# RK3399-AP register map
File version: 1
CPU: CA7 r0p1, little endian, MPU, FPU, I-cache, D-cache, VTOR, 4 interrupt priority bits, 0 interrupts
Registers are 32-bit, read-write, reset 0x0 unless marked. A register's access mark holds for its fields unless they carry their own. Offsets are from the block's base; [hi:lo] are bit positions; {n}, {i} and the like mark numbered series.

## PI0 (part 2 of 2)
Base 0xFFA80800
Same registers: PI1 0xFFA88800
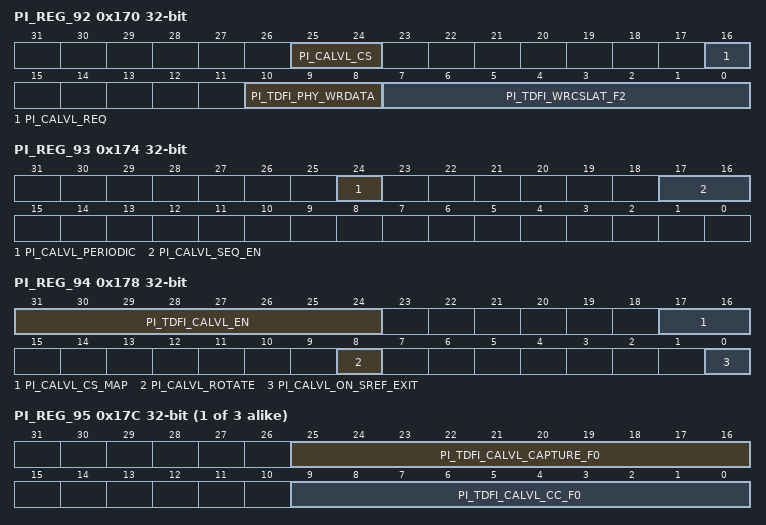
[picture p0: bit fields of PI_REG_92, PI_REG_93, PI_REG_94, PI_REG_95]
0x170 PI_REG_92 access per field — DDR PHY Independent Register 92
  [25:24] PI_CALVL_CS rw — Specifies the target chip select for the CA training operation that is initiated through the PI_REG_92.pi_calvl_req parameter.
  [16] PI_CALVL_REQ wo — Indicates user request to initiate CA training. Set to 1 to trigger.
  [10:8] PI_TDFI_PHY_WRDATA rw — Defines the DFI tPHY_WRDATA timing parameter (in DFI PHY clocks), the maximum cycles between a dfi_wrdata_en assertion and a dfi_wrdata signal.
  [7:0] PI_TDFI_WRCSLAT_F2 rw — Defines the DFI tPHY_WRCSLAT timing parameter (in DFI PHY clocks), the maximum cycles between a write command and a dfi_wrdata_cs_n assertion. The suffix "_f2" of the parameter name is omitted when in non-DFS mode.
0x174 PI_REG_93 — DDR PHY Independent Register 93
  [24] PI_CALVL_PERIODIC — Enables the use of the dfi_lvl_periodic signal during CA training. Set to 1 to enable.
  [17:16] PI_CALVL_SEQ_EN — Specifies the CA training patterns that are to be used. Set to 0 for pattern 0 only, set to 1 for patterns 0 and 1, set to 2 for patterns 0, 1, and 2, or set to 3 for all patterns.
0x178 PI_REG_94 — DDR PHY Independent Register 94
  [31:24] PI_TDFI_CALVL_EN — Defines the DFI tCALVL_EN timing parameter (in DFI clocks), the minimum cycles between a dfi_calvl_en assertion and a dfi_cke de-assertion.
  [17:16] PI_CALVL_CS_MAP — Defines the chip select map for CA training operations. Bit0 controls cs0, bit1 controls cs1. Set each bit to 1 to enable chip for CA training.
  [8] PI_CALVL_ROTATE — Enables rotational chip select for interval CA training. Set to 1 for rotating CS.
  [0] PI_CALVL_ON_SREF_EXIT — Enables automatic CA training on a self-refresh exit. Set to 1 to enable.
{0x0+4i} PI_REG_{i} (i=95..97) — DDR PHY Independent Register {i}
  [25:16] PI_TDFI_CALVL_CAPTURE_F{i-95} — Defines the DFI tCALVL_CAPTURE timing parameter (in DFI clocks), the minimum cycles between a calibration command and a dfi_calvl_capture pulse. The suffix "_f{i-95}" of the parameter name is omitted when in non-DFS mode.
  [9:0] PI_TDFI_CALVL_CC_F{i-95} — Defines the DFI tCALVL_CC timing parameter (in DFI clocks), the minimum cycles between calibration commands. The suffix "_f{i-95}" of the parameter name is omitted when in non-DFS mode.
0x188 PI_REG_98 — DDR PHY Independent Register 98
  [31:0] PI_TDFI_CALVL_RESP — Defines the DFI tCALVL_RESP timing parameter (in DFI clocks), the maximum cycles between a dfi_calvl_req assertion and a dfi_calvl_en assertion.
0x18C PI_REG_99 — DDR PHY Independent Register 99
  [31:0] PI_TDFI_CALVL_MAX — Defines the DFI tCALVL_MAX timing parameter (in DFI clocks), the maximum cycles between a dfi_calvl_en assertion and a valid dfi_calvl_resp.
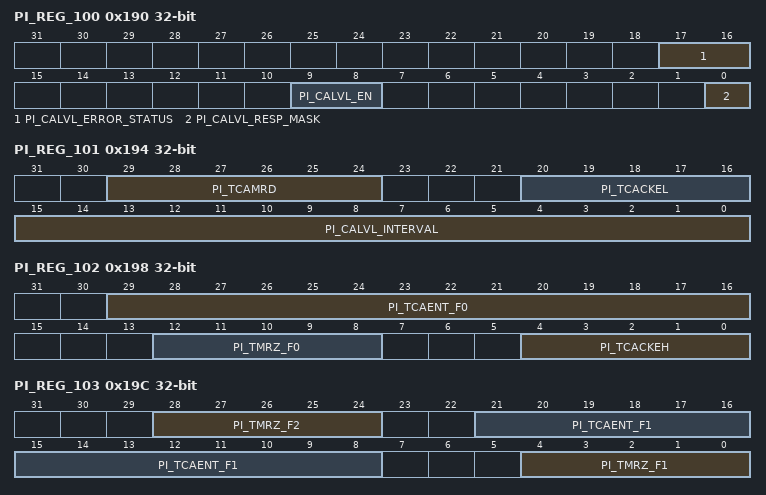
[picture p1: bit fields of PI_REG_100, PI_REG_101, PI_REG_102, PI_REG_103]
0x190 PI_REG_100 access per field — DDR PHY Independent Register 100
  [17:16] PI_CALVL_ERROR_STATUS ro — Holds the error that is associated with the CA training error interrupt. Bit0 set indicates a PI_REG_98.pi_tdfi_calvl_resp parameter violation and bit1 set indicates a PI_REG_99.pi_tdfi_calvl_max parameter violation.
  [9:8] PI_CALVL_EN rw — Enables the PI CA training module. Bit1 represents the support when non-initialization. Bit0 represents the support when initialization. Set to 1 to enable.
  [0] PI_CALVL_RESP_MASK rw — Indicates mask for the dfi_calvl_resp signal during CA training.
0x194 PI_REG_101 — DDR PHY Independent Register 101
  [29:24] PI_TCAMRD — Indicates DRAM TCAMRD value in cycles.
  [20:16] PI_TCACKEL — Indicates DRAM TCACKEL value in cycles.
  [15:0] PI_CALVL_INTERVAL — Indicates the number of long count sequences that is counted between automatic CA training commands.
0x198 PI_REG_102 — DDR PHY Independent Register 102
  [29:16] PI_TCAENT_F0 — Indicates DRAM TCAENT value in cycles. The suffix "_f0" of the parameter name is omitted when in non-DFS mode.
  [12:8] PI_TMRZ_F0 — Indicates DRAM TMRZ value in cycles. The suffix "_f0" of the parameter name is omitted when in non-DFS mode.
  [4:0] PI_TCACKEH — Indicates DRAM TCACKEH value in cycles.
0x19C PI_REG_103 — DDR PHY Independent Register 103
  [28:24] PI_TMRZ_F2 — Indicates DRAM TMRZ value in cycles. The suffix "_f2" of the parameter name is omitted when in non-DFS mode.
  [21:8] PI_TCAENT_F1 — Indicates DRAM TCAENT value in cycles. The suffix "_f1" of the parameter name is omitted when in non-DFS mode.
  [4:0] PI_TMRZ_F1 — Indicates DRAM TMRZ value in cycles. The suffix "_f1" of the parameter name is omitted when in non-DFS mode.
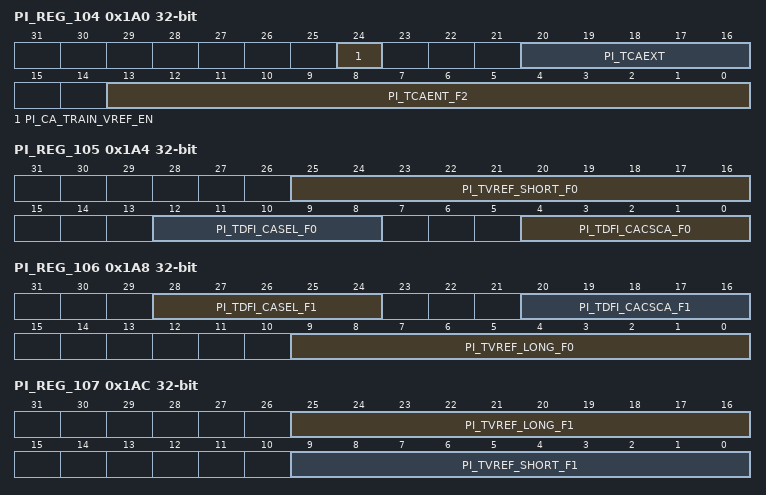
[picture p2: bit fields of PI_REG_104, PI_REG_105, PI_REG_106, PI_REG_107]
0x1A0 PI_REG_104 — DDR PHY Independent Register 104
  [24] PI_CA_TRAIN_VREF_EN — Indicates whether to do VREF training during non-power-on-initial CA training or not. Set to 1 to go through the VREF from start-point for non-power-on-initial CA training. Set to 0 to not update VREF for non-power-on-initial CA training.
  [20:16] PI_TCAEXT — Indicates DRAM TCAEXT value in cycles.
  [13:0] PI_TCAENT_F2 — Indicates DRAM TCAENT value in cycles. The suffix "_f2" of the parameter name is omitted when in non-DFS mode.
0x1A4 PI_REG_105 — DDR PHY Independent Register 105
  [25:16] PI_TVREF_SHORT_F0 — Indicates delay from dfi_calvl_strobe to next CMD (only param_calvl_vref_stepsize change of the VREF). The suffix "_f0" of the parameter name is omitted when in non-DFS mode.
  [12:8] PI_TDFI_CASEL_F0 — Indicates DFI tcalvl_ca_sel timing parameter. The suffix "_f0" of the parameter name is omitted when in non-DFS mode.
  [4:0] PI_TDFI_CACSCA_F0 — Indicates DFI tcalvl_cs_ca timing parameter. The suffix "_f0" of the parameter name is omitted when in non-DFS mode.
0x1A8 PI_REG_106 — DDR PHY Independent Register 106
  [28:24] PI_TDFI_CASEL_F1 — Indicates DFI tcalvl_ca_sel timing parameter. The suffix "_f1" of the parameter name is omitted when in non-DFS mode.
  [20:16] PI_TDFI_CACSCA_F1 — Indicates DFI tcalvl_cs_ca timing parameter. The suffix "_f1" of the parameter name is omitted when in non-DFS mode.
  [9:0] PI_TVREF_LONG_F0 — Indicates delay from dfi_calvl_strobe to next CMD (more than one param_calvl_vref_stepsize Vref change). The suffix "_f0" of the parameter name is omitted when in non-DFS mode.
0x1AC PI_REG_107 — DDR PHY Independent Register 107
  [25:16] PI_TVREF_LONG_F1 — Indicates delay from dfi_calvl_strobe to next CMD (more than one param_calvl_vref_stepsize Vref change). The suffix "_f1" of the parameter name is omitted when in non-DFS mode.
  [9:0] PI_TVREF_SHORT_F1 — Indicates delay from dfi_calvl_strobe to next CMD (only param_calvl_vref_stepsize change of the VREF). The suffix "_f1" of the parameter name is omitted when in non-DFS mode.
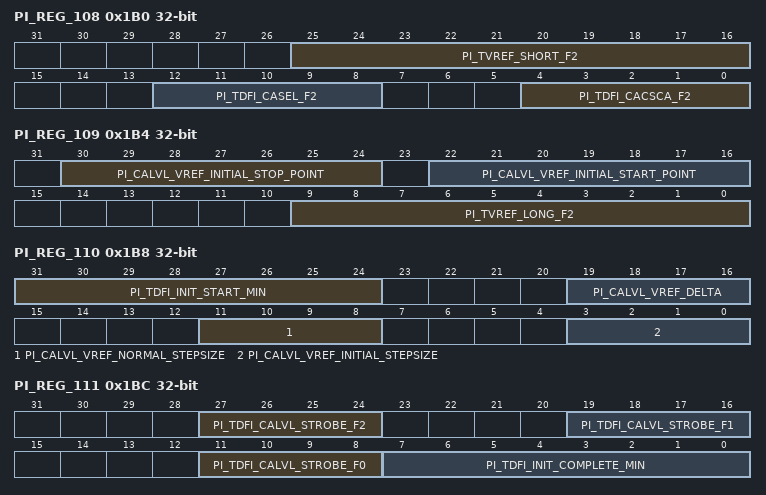
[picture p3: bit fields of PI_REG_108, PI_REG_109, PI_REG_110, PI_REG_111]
0x1B0 PI_REG_108 — DDR PHY Independent Register 108
  [25:16] PI_TVREF_SHORT_F2 — Indicates delay from dfi_calvl_strobe to next CMD (only param_calvl_vref_stepsize change of the VREF). The suffix "_f2" of the parameter name is omitted when in non-DFS mode.
  [12:8] PI_TDFI_CASEL_F2 — Indicates DFI tcalvl_ca_sel timing parameter. The suffix "_f2" of the parameter name is omitted when in non-DFS mode.
  [4:0] PI_TDFI_CACSCA_F2 — Indicates DFI tcalvl_cs_ca timing parameter. The suffix "_f2" of the parameter name is omitted when in non-DFS mode.
0x1B4 PI_REG_109 — DDR PHY Independent Register 109
  [30:24] PI_CALVL_VREF_INITIAL_STOP_POINT — Indicates the end point of VREF for the Vref(ca) training vrefca_range, vref_ca_setting[5:0]
  [22:16] PI_CALVL_VREF_INITIAL_START_POINT — Indicates the start point of VREF for the Vref (ca) training vrefca_range, vref_ca_setting[5:0].
  [9:0] PI_TVREF_LONG_F2 — Indicates delay from dfi_calvl_strobe to next CMD (more than one param_calvl_vref_stepsize Vref change). The suffix "_f2" of the parameter name is omitted when in non-DFS mode.
0x1B8 PI_REG_110 — DDR PHY Independent Register 110
  [31:24] PI_TDFI_INIT_START_MIN — Indicates the minimum number of DFI clocks before dfi_init_start can be driven after a previous command or training event.
  [19:16] PI_CALVL_VREF_DELTA — Indicates the CA VREF adjustment for non-initial CA training.
  [11:8] PI_CALVL_VREF_NORMAL_STEPSIZE — Indicates the adjust step for the Vref(ca) training.
  [3:0] PI_CALVL_VREF_INITIAL_STEPSIZE — Indicates the adjust step for the Vref(ca) training.
0x1BC PI_REG_111 — DDR PHY Independent Register 111
  [27:24] PI_TDFI_CALVL_STROBE_F2 — Indicates data setup for VREF training mode. The suffix "_f2" of the parameter name is omitted when in non-DFS mode.
  [19:16] PI_TDFI_CALVL_STROBE_F1 — Indicates data setup for VREF training mode. The suffix "_f1" of the parameter name is omitted when in non-DFS mode.
  [11:8] PI_TDFI_CALVL_STROBE_F0 — Indicates data setup for VREF training mode. The suffix "_f0" of the parameter name is omitted when in non-DFS mode.
  [7:0] PI_TDFI_INIT_COMPLETE_MIN — Indicates the minimum number of DFI clocks from dfi_init_complete to a command or training event.
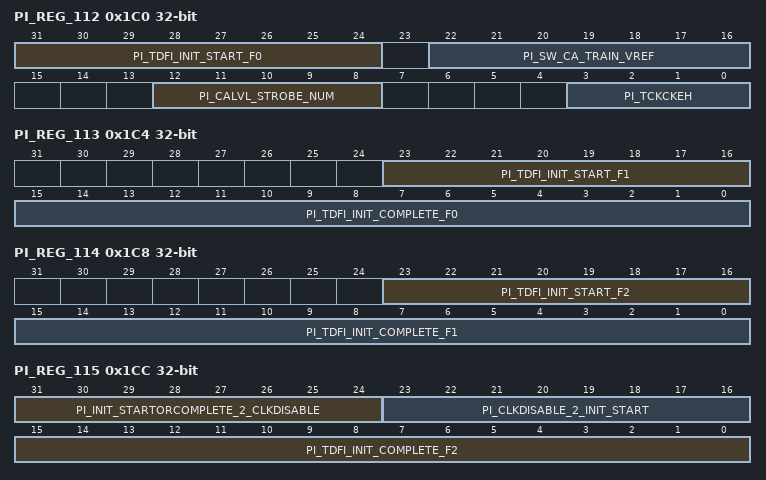
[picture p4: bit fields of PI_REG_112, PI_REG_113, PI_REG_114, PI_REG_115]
0x1C0 PI_REG_112 — DDR PHY Independent Register 112
  [31:24] PI_TDFI_INIT_START_F0 — Defines the DFI tINIT_START timing parameter (in DFI clocks), the maximum number or cycles between a dfi_init_start assertion and a dfi_init_complete de-assertion from the PHY. The suffix "_f0" of the parameter name is omitted when in non-DFS mode.
  [22:16] PI_SW_CA_TRAIN_VREF — Indicates the VREF value, which is set for software step-by-step CA training.
  [12:8] PI_CALVL_STROBE_NUM — Indicates the consecutive dfi_calvl_strobe number when updating the CA VREF data.
  [3:0] PI_TCKCKEH — Indicates clock and command are valid before CKE HIGH.
0x1C4 PI_REG_113 — DDR PHY Independent Register 113
  [23:16] PI_TDFI_INIT_START_F1 — Defines the DFI tINIT_START timing parameter (in DFI clocks), the maximum number or cycles between a dfi_init_start assertion and a dfi_init_complete de-assertion from the PHY. The suffix "_f1" of the parameter name is omitted when in non-DFS mode.
  [15:0] PI_TDFI_INIT_COMPLETE_F0 — Defines the DFI tINIT_COMPLETE timing parameter (in DFI clocks), the maximum cycles between a dfi_init_start de-assertion and a dfi_init_complete assertion from the PHY. The suffix "_f0" of the parameter name is omitted when in non-DFS mode
0x1C8 PI_REG_114 — DDR PHY Independent Register 114
  [23:16] PI_TDFI_INIT_START_F2 — Defines the DFI tINIT_START timing parameter (in DFI clocks), the maximum number or cycles between a dfi_init_start assertion and a dfi_init_complete de-assertion from the PHY. The suffix "_f2" of the parameter name is omitted when in non-DFS mode.
  [15:0] PI_TDFI_INIT_COMPLETE_F1 — Defines the DFI tINIT_COMPLETE timing parameter (in DFI clocks), the maximum cycles between a dfi_init_start de-assertion and a dfi_init_complete assertion from the PHY. The suffix "_f1" of the parameter name is omitted when in non-DFS mode
0x1CC PI_REG_115 — DDR PHY Independent Register 115
  [31:24] PI_INIT_STARTORCOMPLETE_2_CLKDISABLE — Defines the delay from deasserting of dfi_init_start or asserting of dfi_init_complete to deasserting of dfi_dram_clk_disable in DFI clock.
  [23:16] PI_CLKDISABLE_2_INIT_START — Defines the delay from the asserting of dfi_dram_clk_disable to the asserting of dfi_init_start in DFI clock.
  [15:0] PI_TDFI_INIT_COMPLETE_F2 — Defines the DFI tINIT_COMPLETE timing parameter (in DFI clocks), the maximum cycles between a dfi_init_start de-assertion and a dfi_init_complete assertion from the PHY. The suffix "_f2" of the parameter name is omitted when in non-DFS mode
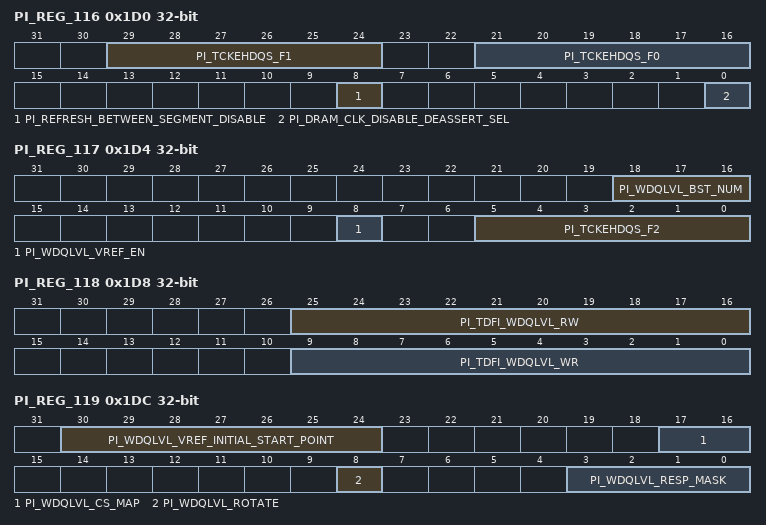
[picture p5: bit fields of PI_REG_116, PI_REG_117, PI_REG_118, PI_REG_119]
0x1D0 PI_REG_116 — DDR PHY Independent Register 116
  [29:24] PI_TCKEHDQS_F1 — Indicates the DRAM timing TCKEHDQS, minimum delay from CKE high to strobe high impedance. The suffix "_f1" of the parameter name is omitted when in non-DFS mode.
  [21:16] PI_TCKEHDQS_F0 — Indicates the DRAM timing TCKEHDQS, minimum delay from CKE high to strobe high impedance. The suffix "_f0" of the parameter name is omitted when in non-DFS mode.
  [8] PI_REFRESH_BETWEEN_SEGMENT_DISABLE — Disables the refresh between CA first and second segment training. Defaut is set to 1.
  [0] PI_DRAM_CLK_DISABLE_DEASSERT_SEL — Indicates dfi_dram_clk_disable deassert following dfi_init_start deassert or dfi_init_complete assert. 1\'b0: dfi_dram_clk_disable deassert following dfi_init_start deassert. 1\'b1: dfi_dram_clk_disable deassert following dfi_init_complete assert.
0x1D4 PI_REG_117 — DDR PHY Independent Register 117
  [18:16] PI_WDQLVL_BST_NUM — Indicates burst number for MPC, the maximum FIFO for LPDDR4 is 5.
  [8] PI_WDQLVL_VREF_EN — Indicates whether to do VREF training for non-initial WDQ leveling
  [5:0] PI_TCKEHDQS_F2 — Indicates the DRAM timing TCKEHDQS, minimum delay from CKE high to strobe high impedance. The suffix "_f2" of the parameter name is omitted when in non-DFS mode.
0x1D8 PI_REG_118 — DDR PHY Independent Register 118
  [25:16] PI_TDFI_WDQLVL_RW — Switches time from read to write.
  [9:0] PI_TDFI_WDQLVL_WR — Switches time from write to read.
0x1DC PI_REG_119 — DDR PHY Independent Register 119
  [30:24] PI_WDQLVL_VREF_INITIAL_START_POINT — Indicates write DQ training VREF start value.
  [17:16] PI_WDQLVL_CS_MAP — Indicates map of chip selects that are included in write DQ training sequence.
  [8] PI_WDQLVL_ROTATE — Enables write DQ training rotate for periodic training.
  [3:0] PI_WDQLVL_RESP_MASK — Indicates write DQ training response mask.
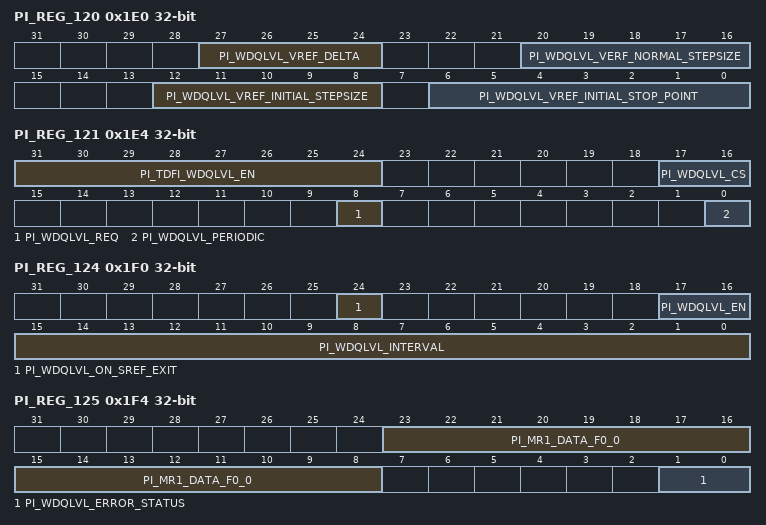
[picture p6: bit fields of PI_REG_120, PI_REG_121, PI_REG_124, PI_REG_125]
0x1E0 PI_REG_120 — DDR PHY Independent Register 120
  [27:24] PI_WDQLVL_VREF_DELTA — Indicates the WDQ VREF adjustment for non-initial WDQ training.
  [20:16] PI_WDQLVL_VERF_NORMAL_STEPSIZE — Indicates write DQ training VREF step size.
  [12:8] PI_WDQLVL_VREF_INITIAL_STEPSIZE — Indicates write DQ training VREF step size.
  [6:0] PI_WDQLVL_VREF_INITIAL_STOP_POINT — Indicates write DQ training VREF stop value.
0x1E4 PI_REG_121 access per field — DDR PHY Independent Register 121
  [31:24] PI_TDFI_WDQLVL_EN rw — Indicates DFI timing param - enable to FIFO write.
  [17:16] PI_WDQLVL_CS rw — Indicates write DQ training target chip select.
  [8] PI_WDQLVL_REQ wo — Indicates software write DQ training request.
  [0] PI_WDQLVL_PERIODIC rw — Enables write DQ training periodic.
0x1E8 PI_REG_122 — DDR PHY Independent Register 122
  [31:0] PI_TDFI_WDQLVL_RESP — Indicates DFI timing param - req to enable.
0x1EC PI_REG_123 — DDR PHY Independent Register 123
  [31:0] PI_TDFI_WDQLVL_MAX — Indicates DFI timing param - max enable to resp (PHY eval).
0x1F0 PI_REG_124 — DDR PHY Independent Register 124
  [24] PI_WDQLVL_ON_SREF_EXIT — Issues a write DQ training command on self-refresh exit.
  [17:16] PI_WDQLVL_EN — Indicates if write DQ leveling is enabled. Bit1 represents the support when non-initialization. Bit0 represents the support when initialization.
  [15:0] PI_WDQLVL_INTERVAL — Indicates write DQ train interval counter program value.
0x1F4 PI_REG_125 access per field — DDR PHY Independent Register 125
  [23:8] PI_MR1_DATA_F0_0 rw — Indicates data to program into memory mode register 1 for chip select 0. The suffix "_f0" of the parameter name is omitted when in non-DFS mode.
  [1:0] PI_WDQLVL_ERROR_STATUS ro — Holds the error associated with the write DQ level error interrupt. Bit0 set indicates a PI_REG_123.pi_tdfi_wdqlvl_max parameter violation and bit1 set indicates a PI_REG_122.pi_tdfi_wdqlvl_resp parameter violation.
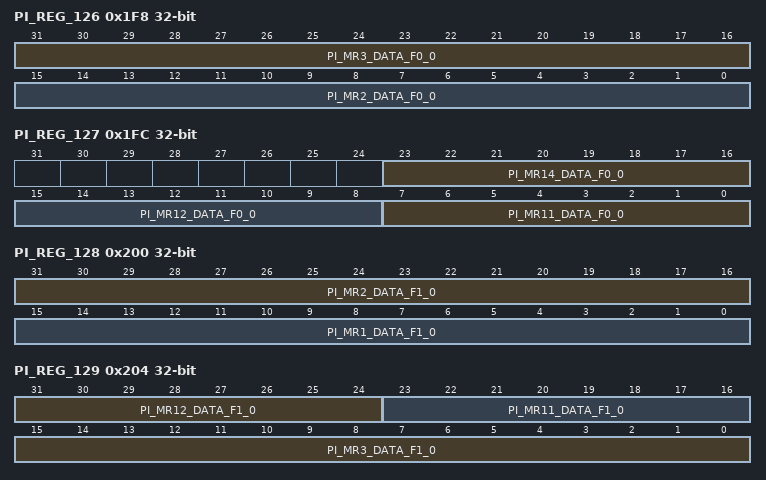
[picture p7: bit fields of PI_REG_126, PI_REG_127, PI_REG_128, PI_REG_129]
0x1F8 PI_REG_126 — DDR PHY Independent Register 126
  [31:16] PI_MR3_DATA_F0_0 — Indicates data to program into memory mode register 3 for chip select 0. The suffix "_f0" of the parameter name is omitted when in non-DFS mode.
  [15:0] PI_MR2_DATA_F0_0 — Indicates data to program into memory mode register 2 for chip select 0. The suffix "_f0" of the parameter name is omitted when in non-DFS mode.
0x1FC PI_REG_127 — DDR PHY Independent Register 127
  [23:16] PI_MR14_DATA_F0_0 — Indicates data to program into memory mode register 14 for chip select 0. The suffix "_f0" of the parameter name is omitted when in non-DFS mode.
  [15:8] PI_MR12_DATA_F0_0 — Indicates data to program into memory mode register 12 for chip select 0. The suffix "_f0" of the parameter name is omitted when in non-DFS mode.
  [7:0] PI_MR11_DATA_F0_0 — Indicates data to program into memory mode register 11 for chip select 0. The suffix "_f0" of the parameter name is omitted when in non-DFS mode.
0x200 PI_REG_128 — DDR PHY Independent Register 128
  [31:16] PI_MR2_DATA_F1_0 — Indicates data to program into memory mode register 2 for chip select 0. The suffix "_f1" of the parameter name is omitted when in non-DFS mode.
  [15:0] PI_MR1_DATA_F1_0 — Indicates data to program into memory mode register 1 for chip select 0. The suffix "_f1" of the parameter name is omitted when in non-DFS mode.
0x204 PI_REG_129 — DDR PHY Independent Register 129
  [31:24] PI_MR12_DATA_F1_0 — Indicates data to program into memory mode register 12 for chip select 0. The suffix "_f1" of the parameter name is omitted when in non-DFS mode.
  [23:16] PI_MR11_DATA_F1_0 — Indicates data to program into memory mode register 11 for chip select 0. The suffix "_f1" of the parameter name is omitted when in non-DFS mode.
  [15:0] PI_MR3_DATA_F1_0 — Indicates data to program into memory mode register 3 for chip select 0. The suffix "_f1" of the parameter name is omitted when in non-DFS mode.
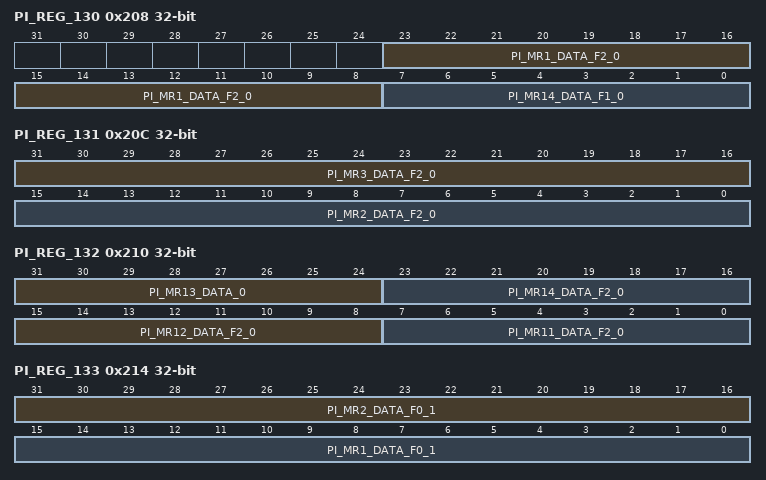
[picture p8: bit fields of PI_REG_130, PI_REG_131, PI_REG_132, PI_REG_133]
0x208 PI_REG_130 — DDR PHY Independent Register 130
  [23:8] PI_MR1_DATA_F2_0 — Indicates data to program into memory mode register 1 for chip select 0. The suffix "_f2" of the parameter name is omitted when in non-DFS mode.
  [7:0] PI_MR14_DATA_F1_0 — Indicates data to program into memory mode register 14 for chip select 0. The suffix "_f1" of the parameter name is omitted when in non-DFS mode.
0x20C PI_REG_131 — DDR PHY Independent Register 131
  [31:16] PI_MR3_DATA_F2_0 — Indicates data to program into memory mode register 3 for chip select 0. The suffix "_f2" of the parameter name is omitted when in non-DFS mode.
  [15:0] PI_MR2_DATA_F2_0 — Indicates data to program into memory mode register 2 for chip select 0. The suffix "_f2" of the parameter name is omitted when in non-DFS mode.
0x210 PI_REG_132 — DDR PHY Independent Register 132
  [31:24] PI_MR13_DATA_0 — Indicates data to program into memory mode register 13 for chip select 0.
  [23:16] PI_MR14_DATA_F2_0 — Indicates data to program into memory mode register 14 for chip select 0. The suffix "_f2" of the parameter name is omitted when in non-DFS mode.
  [15:8] PI_MR12_DATA_F2_0 — Indicates data to program into memory mode register 12 for chip select 0. The suffix "_f2" of the parameter name is omitted when in non-DFS mode.
  [7:0] PI_MR11_DATA_F2_0 — Indicates data to program into memory mode register 11 for chip select 0. The suffix "_f2" of the parameter name is omitted when in non-DFS mode.
0x214 PI_REG_133 — DDR PHY Independent Register 133
  [31:16] PI_MR2_DATA_F0_1 — Indicates data to program into memory mode register 2 for chip select 1. The suffix "_f0" of the parameter name is omitted when in non-DFS mode.
  [15:0] PI_MR1_DATA_F0_1 — Indicates data to program into memory mode register 1 for chip select 1. The suffix "_f0" of the parameter name is omitted when in non-DFS mode.
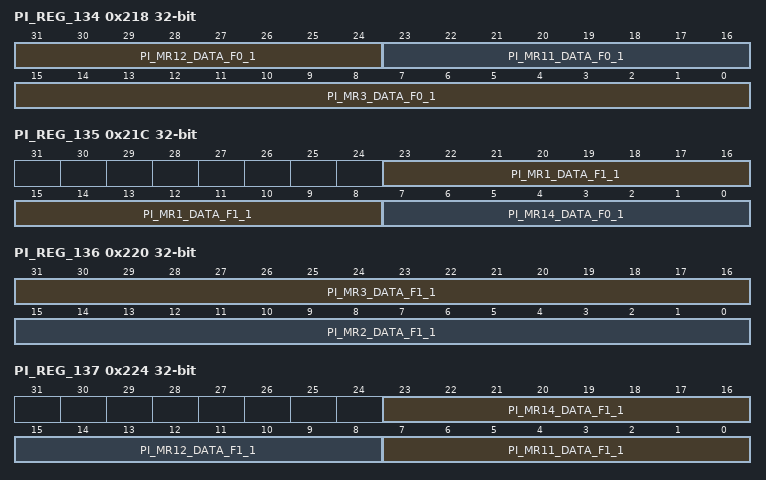
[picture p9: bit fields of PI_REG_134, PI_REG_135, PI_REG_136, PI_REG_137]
0x218 PI_REG_134 — DDR PHY Independent Register 134
  [31:24] PI_MR12_DATA_F0_1 — Indicates data to program into memory mode register 12 for chip select 1. The suffix "_f0" of the parameter name is omitted when in non-DFS mode.
  [23:16] PI_MR11_DATA_F0_1 — Indicates data to program into memory mode register 11 for chip select 1. The suffix "_f0" of the parameter name is omitted when in non-DFS mode.
  [15:0] PI_MR3_DATA_F0_1 — Indicates data to program into memory mode register 3 for chip select 1. The suffix "_f0" of the parameter name is omitted when in non-DFS mode.
0x21C PI_REG_135 — DDR PHY Independent Register 135
  [23:8] PI_MR1_DATA_F1_1 — Indicates data to program into memory mode register 1 for chip select 1. The suffix "_f1" of the parameter name is omitted when in non-DFS mode.
  [7:0] PI_MR14_DATA_F0_1 — Indicates data to program into memory mode register 14 for chip select 1. The suffix "_f0" of the parameter name is omitted when in non-DFS mode.
0x220 PI_REG_136 — DDR PHY Independent Register 136
  [31:16] PI_MR3_DATA_F1_1 — Indicates data to program into memory mode register 3 for chip select 1. The suffix "_f1" of the parameter name is omitted when in non-DFS mode.
  [15:0] PI_MR2_DATA_F1_1 — Indicates data to program into memory mode register 2 for chip select 1. The suffix "_f1" of the parameter name is omitted when in non-DFS mode.
0x224 PI_REG_137 — DDR PHY Independent Register 137
  [23:16] PI_MR14_DATA_F1_1 — Indicates data to program into memory mode register 14 for chip select 1. The suffix "_f1" of the parameter name is omitted when in non-DFS mode.
  [15:8] PI_MR12_DATA_F1_1 — Indicates data to program into memory mode register 12 for chip select 1. The suffix "_f1" of the parameter name is omitted when in non-DFS mode.
  [7:0] PI_MR11_DATA_F1_1 — Indicates data to program into memory mode register 11 for chip select 1. The suffix "_f1" of the parameter name is omitted when in non-DFS mode.
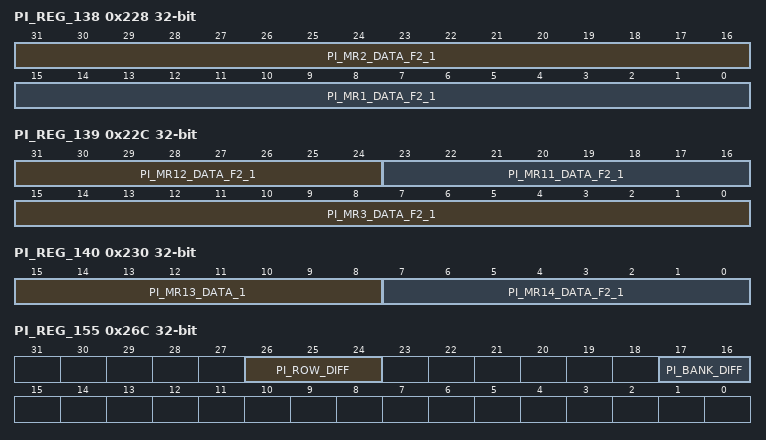
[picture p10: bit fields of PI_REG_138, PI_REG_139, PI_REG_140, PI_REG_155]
0x228 PI_REG_138 — DDR PHY Independent Register 138
  [31:16] PI_MR2_DATA_F2_1 — Indicates data to program into memory mode register 2 for chip select 1. The suffix "_f2" of the parameter name is omitted when in non-DFS mode.
  [15:0] PI_MR1_DATA_F2_1 — Indicates data to program into memory mode register 1 for chip select 1. The suffix "_f2" of the parameter name is omitted when in non-DFS mode.
0x22C PI_REG_139 — DDR PHY Independent Register 139
  [31:24] PI_MR12_DATA_F2_1 — Indicates data to program into memory mode register 12 for chip select 1. The suffix "_f2" of the parameter name is omitted when in non-DFS mode.
  [23:16] PI_MR11_DATA_F2_1 — Indicates data to program into memory mode register 11 for chip select 1. The suffix "_f2" of the parameter name is omitted when in non-DFS mode.
  [15:0] PI_MR3_DATA_F2_1 — Indicates data to program into memory mode register 3 for chip select 1. The suffix "_f2" of the parameter name is omitted when in non-DFS mode.
0x230 PI_REG_140 — DDR PHY Independent Register 140
  [15:8] PI_MR13_DATA_1 — Indicates data to program into memory mode register 13 for chip select 0.
  [7:0] PI_MR14_DATA_F2_1 — Indicates data to program into memory mode register 14 for chip select 1. The suffix "_f2" of the parameter name is omitted when in non-DFS mode.
0x26C PI_REG_155 — DDR PHY Independent Register 155
  [26:24] PI_ROW_DIFF — Indicates the difference between the number of address pins available and the number being used.
  [17:16] PI_BANK_DIFF — Indicates encoded number of banks on the DRAM(s).
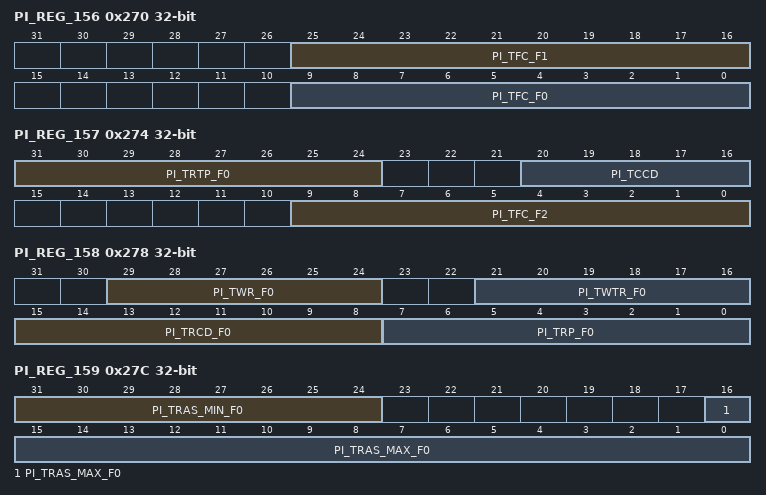
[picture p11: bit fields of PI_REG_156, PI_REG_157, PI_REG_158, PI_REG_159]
0x270 PI_REG_156 — DDR PHY Independent Register 156
  [25:16] PI_TFC_F1 — Indicates the delay in PHY clock cycles from setting MR13.OP7 to any valid command. The suffix "_f1" of the parameter name is omitted when in non-DFS mode.
  [9:0] PI_TFC_F0 — Indicates the delay in PHY clock cycles from setting MR13.OP7 to any valid command. The suffix "_f0" of the parameter name is omitted when in non-DFS mode.
0x274 PI_REG_157 — DDR PHY Independent Register 157
  [31:24] PI_TRTP_F0 — Indicates DRAM TRTP value in cycles. The suffix "_f0" of the parameter name is omitted when in non-DFS mode.
  [20:16] PI_TCCD — Indicates DRAM CAS-to-CAS value in cycles.
  [9:0] PI_TFC_F2 — Indicates the delay in PHY clock cycles from setting MR13.OP7 to any valid command. The suffix "_f2" of the parameter name is omitted when in non-DFS mode.
0x278 PI_REG_158 — DDR PHY Independent Register 158
  [29:24] PI_TWR_F0 — Indicates DRAM TWR value in cycles. The suffix "_f0" of the parameter name is omitted when in non-DFS mode.
  [21:16] PI_TWTR_F0 — Indicates DRAM TWTR value in cycles. The suffix "_f0" of the parameter name is omitted when in non-DFS mode.
  [15:8] PI_TRCD_F0 — Indicates DRAM TRCD value in cycles. The suffix "_f0" of the parameter name is omitted when in non-DFS mode.
  [7:0] PI_TRP_F0 — Indicates DRAM TRP value in cycles. The suffix "_f0" of the parameter name is omitted when in non-DFS mode.
0x27C PI_REG_159 — DDR PHY Independent Register 159
  [31:24] PI_TRAS_MIN_F0 — Indicates DRAM TRAS_MIN value in cycles. The suffix "_f0" of the parameter name is omitted when in non-DFS mode.
  [16:0] PI_TRAS_MAX_F0 — Indicates DRAM TRAS_MAX value in cycles. The suffix "_f0" of parameter name will be omitted when non DFS mode.
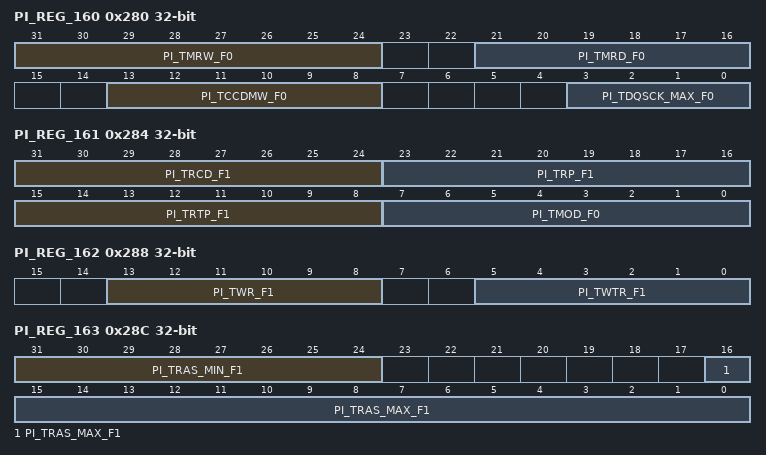
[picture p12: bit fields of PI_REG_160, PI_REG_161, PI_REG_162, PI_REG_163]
0x280 PI_REG_160 — DDR PHY Independent Register 160
  [31:24] PI_TMRW_F0 — Indicates DRAM TMRW value in cycles. The suffix "_f0" of the parameter name is omitted when in non-DFS mode.
  [21:16] PI_TMRD_F0 — Indicates DRAM TMRD value in cycles. The suffix "_f0" of the parameter name is omitted when in non-DFS mode.
  [13:8] PI_TCCDMW_F0 — Indicates LPDDR4 DRAM TCCDMW in cycles. The suffix "_f0" of the parameter name is omitted when in non-DFS mode.
  [3:0] PI_TDQSCK_MAX_F0 — Indicates additional delay that is needed for tDQSCK. The suffix "_f0" of the parameter name is omitted when in non-DFS mode.
0x284 PI_REG_161 — DDR PHY Independent Register 161
  [31:24] PI_TRCD_F1 — Indicates DRAM TRCD value in cycles. The suffix "_f1" of the parameter name is omitted when in non-DFS mode.
  [23:16] PI_TRP_F1 — Indicates DRAM TRP value in cycles. The suffix "_f1" of the parameter name is omitted when in non-DFS mode.
  [15:8] PI_TRTP_F1 — Indicates DRAM TRTP value in cycles. The suffix "_f1" of the parameter name is omitted when in non-DFS mode.
  [7:0] PI_TMOD_F0 — Indicates TMOD value in cycles. The suffix "_f0" of the parameter name is omitted when in non-DFS mode.
0x288 PI_REG_162 — DDR PHY Independent Register 162
  [13:8] PI_TWR_F1 — Indicates DRAM TWR value in cycles. The suffix "_f1" of the parameter name is omitted when in non-DFS mode.
  [5:0] PI_TWTR_F1 — Indicates DRAM TWTR value in cycles. The suffix "_f1" of the parameter name is omitted when in non-DFS mode.
0x28C PI_REG_163 — DDR PHY Independent Register 163
  [31:24] PI_TRAS_MIN_F1 — Indicates DRAM TRAS_MIN value in cycles. The suffix "_f1" of the parameter name is omitted when in non-DFS mode.
  [16:0] PI_TRAS_MAX_F1 — Indicates DRAM TRAS_MAX value in cycles. The suffix "_f1" of parameter name will be omitted when non DFS mode.
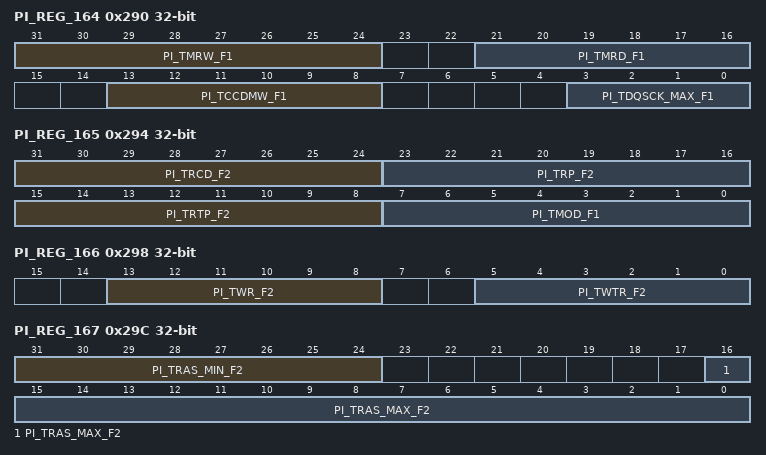
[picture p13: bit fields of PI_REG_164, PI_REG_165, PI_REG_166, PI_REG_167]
0x290 PI_REG_164 — DDR PHY Independent Register 164
  [31:24] PI_TMRW_F1 — Indicates DRAM TMRW value in cycles. The suffix "_f1" of the parameter name is omitted when in non-DFS mode.
  [21:16] PI_TMRD_F1 — Indicates DRAM TMRD value in cycles. The suffix "_f1" of the parameter name is omitted when in non-DFS mode.
  [13:8] PI_TCCDMW_F1 — Indicates LPDDR4 DRAM TCCDMW in cycles. The suffix "_f1" of the parameter name is omitted when in non-DFS mode.
  [3:0] PI_TDQSCK_MAX_F1 — Indicates additional delay that is needed for tDQSCK. The suffix "_f1" of the parameter name is omitted when in non-DFS mode.
0x294 PI_REG_165 — DDR PHY Independent Register 165
  [31:24] PI_TRCD_F2 — Indicates DRAM TRCD value in cycles. The suffix "_f2" of the parameter name is omitted when in non-DFS mode.
  [23:16] PI_TRP_F2 — Indicates DRAM TRP value in cycles. The suffix "_f2" of the parameter name is omitted when in non-DFS mode.
  [15:8] PI_TRTP_F2 — Indicates DRAM TRTP value in cycles. The suffix "_f2" of the parameter name is omitted when in non-DFS mode.
  [7:0] PI_TMOD_F1 — Indicates TMOD value in cycles. The suffix "_f1" of the parameter name is omitted when in non-DFS mode.
0x298 PI_REG_166 — DDR PHY Independent Register 166
  [13:8] PI_TWR_F2 — Indicates DRAM TWR value in cycles. The suffix "_f2" of the parameter name is omitted when in non-DFS mode.
  [5:0] PI_TWTR_F2 — Indicates DRAM TWTR value in cycles. The suffix "_f2" of the parameter name is omitted when in non-DFS mode.
0x29C PI_REG_167 — DDR PHY Independent Register 167
  [31:24] PI_TRAS_MIN_F2 — Indicates DRAM TRAS_MIN value in cycles. The suffix "_f2" of the parameter name is omitted when in non-DFS mode.
  [16:0] PI_TRAS_MAX_F2 — Indicates DRAM TRAS_MAX value in cycles. The suffix "_f2" of parameter name will be omitted when non DFS mode.
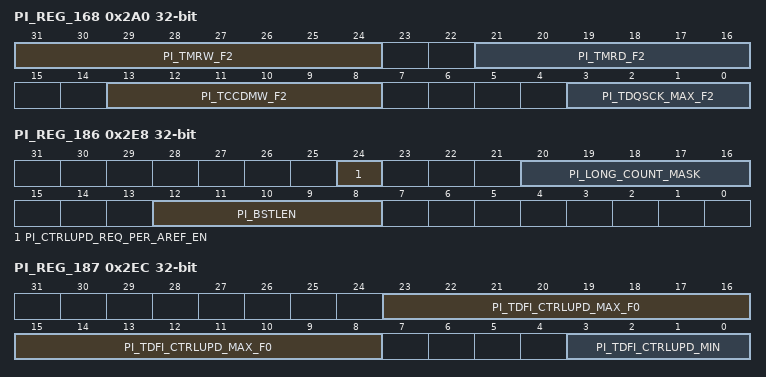
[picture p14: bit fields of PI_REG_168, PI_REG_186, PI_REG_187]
0x2A0 PI_REG_168 — DDR PHY Independent Register 168
  [31:24] PI_TMRW_F2 — Indicates DRAM TMRW value in cycles. The suffix "_f2" of the parameter name is omitted when in non-DFS mode.
  [21:16] PI_TMRD_F2 — Indicates DRAM TMRD value in cycles. The suffix "_f2" of the parameter name is omitted when in non-DFS mode.
  [13:8] PI_TCCDMW_F2 — Indicates LPDDR4 DRAM TCCDMW in cycles. The suffix "_f2" of the parameter name is omitted when in non-DFS mode.
  [3:0] PI_TDQSCK_MAX_F2 — Indicates additional delay that is needed for tDQSCK. The suffix "_f2" of the parameter name is omitted when in non-DFS mode.
0x2A4 PI_REG_169 — DDR PHY Independent Register 169
  [7:0] PI_TMOD_F2 — Indicates TMOD value in cycles. The suffix "_f2" of the parameter name is omitted when in non-DFS mode.
0x2B8 PI_REG_174 ro — DDR PHY Independent Register 174
  [25:8] PI_INT_STATUS — Indicates status of interrupt features in the PI.
0x2BC PI_REG_175 wo — DDR PHY Independent Register 175
  [17:0] PI_INT_ACK — Clears the corresponding interrupt bit of the PI_REG_174.pi_int_status parameter.
0x2C0 PI_REG_176 — DDR PHY Independent Register 176
  [17:0] PI_INT_MASK — Indicates mask for PI interrupt signals from the PI_REG_174.pi_int_status parameter.
0x2E8 PI_REG_186 — DDR PHY Independent Register 186
  [24] PI_CTRLUPD_REQ_PER_AREF_EN — Enables an automatic PI-initiated update (dfi_ctrlupd_req) after every refresh. Set to 1 to enable.
  [20:16] PI_LONG_COUNT_MASK — Reduces the length of the long counter from 1024 cycles. The only supported values are 0x00 (1024 cycles), 0x10 (512 clocks), 0x18 (256 clocks), 0x1C (128 clocks), 0x1E (64 clocks), and 0x1F (32 clocks).
  [12:8] PI_BSTLEN — Indicates encoded burst length that is sent to DRAMs during initialization. Set to 1 for BL2, set to 2 for BL4, or set to 3 for BL8.
0x2EC PI_REG_187 access per field — DDR PHY Independent Register 187
  [23:8] PI_TDFI_CTRLUPD_MAX_F0 rw — Defines the DFI tCTRLUPD_MAX timing parameter (in DFI clocks), the maximum cycles that dfi_ctrlupd_req can be asserted. If programmed to a non-zero, a timing violation causes an interrupt and bit (1) set in the PI_REG_193.pi_update_error_status parameter. The suffix "_f0" of the parameter name is omitted when in non-DFS mode.
  [3:0] PI_TDFI_CTRLUPD_MIN ro — Reports the DFI tCTRLUPD_MIN timing parameter (in DFI clocks), the minimum cycles that dfi_ctrlupd_req must be asserted.
0x2F0 PI_REG_188 — DDR PHY Independent Register 188
  [31:0] PI_TDFI_CTRLUPD_INTERVAL_F0 — Defines the DFI tCTRLUPD_INTERVAL timing parameter (in DFI clocks), the maximum cycles between dfi_ctrlupd_req assertions. If programmed to a non-zero, a timing violation causes an interrupt and bit0 set in the PI_REG_193.pi_update_error_status parameter. The suffix "_f0" of the parameter name is omitted when in non-DFS mode.
0x2F4 PI_REG_189 — DDR PHY Independent Register 189
  [15:0] PI_TDFI_CTRLUPD_MAX_F1 — Defines the DFI tCTRLUPD_MAX timing parameter (in DFI clocks), the maximum cycles that dfi_ctrlupd_req can be asserted. If programmed to a non-zero, a timing violation causes an interrupt and bit (1) set in the PI_REG_193.pi_update_error_status parameter. The suffix "_f1" of the parameter name is omitted when in non-DFS mode.
0x2F8 PI_REG_190 — DDR PHY Independent Register 190
  [31:0] PI_TDFI_CTRLUPD_INTERVAL_F1 — Defines the DFI tCTRLUPD_INTERVAL timing parameter (in DFI clocks), the maximum cycles between dfi_ctrlupd_req assertions. If programmed to a non-zero, a timing violation causes an interrupt and bit0 set in the PI_REG_193.pi_update_error_status parameter. The suffix "_f1" of the parameter name is omitted when in non-DFS mode.
0x2FC PI_REG_191 — DDR PHY Independent Register 191
  [15:0] PI_TDFI_CTRLUPD_MAX_F2 — Defines the DFI tCTRLUPD_MAX timing parameter (in DFI clocks), the maximum cycles that dfi_ctrlupd_req can be asserted. If programmed to a non-zero, a timing violation causes an interrupt and bit (1) set in the PI_REG_193.pi_update_error_status parameter. The suffix "_f2" of the parameter name is omitted when in non-DFS mode.
0x300 PI_REG_192 — DDR PHY Independent Register 192
  [31:0] PI_TDFI_CTRLUPD_INTERVAL_F2 — Defines the DFI tCTRLUPD_INTERVAL timing parameter (in DFI clocks), the maximum cycles between dfi_ctrlupd_req assertions. If programmed to a non-zero, a timing violation causes an interrupt and bit0 set in the PI_REG_193.pi_update_error_status parameter. The suffix "_f2" of the parameter name is omitted when in non-DFS mode.
0x304 PI_REG_193 ro — DDR PHY Independent Register 193
  [6:0] PI_UPDATE_ERROR_STATUS — Identifies the source of any DFI PI-initiated or PHY-initiated update errors. A value of 1 indicates a timing violation of the associated timing parameter. Bit 5-0: phyupd_resp_error, phyupd_type3_error, phyupd_type2_error, phyupd_type1_error, ctrlupd_max_error, ctrlupd_interval_error.
0x31C PI_REG_199 — DDR PHY Independent Register 199
  [3:0] PI_COL_DIFF — Indicates the difference between the number of column pins available and the number being used. write_enable bit0~15 write enable When bit 16=1, bit 0 can be written by software. When bit 16=0, bit 0 cannot be written by software; When bit 17=1, bit 1 can be written by software. When bit 17=0, bit 1 cannot be written by software; ...... When bit 31=1, bit 15 can be written by software. When bit 31=0, bit 15 cannot be written by software; reserved ddr0_cntrl_freq_change_ack Channel 0 DDR controller frequency change acknowledge ddr0_cntrl_freq_change_ack Channel 0 DDR controller frequency change acknowledge Ddr1_freq_change_ack Channel 1 DDR PHY frequency change acknowledge ddr0_freq_change_ack Channel 0 DDR PHY frequency change acknowledge reserved chg_fc_reg_copy Select the copy of timing parameters that will be used after frequency change. reserved fail_cont_en When frequency change fail, whether continue to enable change. chg_freq_finish Frequency change finish 1\'b0: not finish 1\'b1: finish chg_req Frequency change request 1\'b0: not request 1\'b1: request
